VERSION ""

NS_ :

BS_:

BU_: LDS4 SCU_B SCU_A GCU_B GCU_A StreetDrone
VAL_TABLE_ GCU_A_State 15 "ERROR" 5 "SAFE_GCU_B_DISABLED" 4 "SAFE" 3 "AUTO" 2 "MANUAL" 1 "IN IT" 0 "UNKNOWN" ;
VAL_TABLE_ False_True 597 "True" 0 "False" ;

BO_ 50 SCU_B_Data_3: 8 SCU_B
 SG_ Brake_Torque_1_Control : 0|16@1- (0.01,0) [-327.68|327.67] "Nm"  LDS4,GCU_B,GCU_A

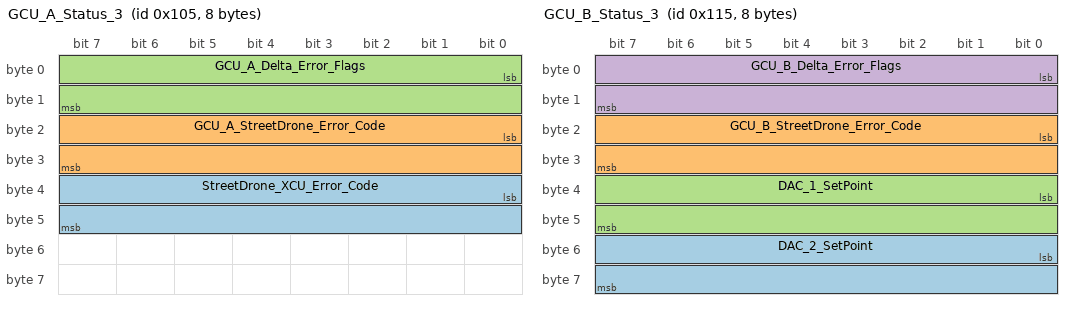
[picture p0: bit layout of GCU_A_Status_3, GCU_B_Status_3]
BO_ 261 GCU_A_Status_3: 8 GCU_A
 SG_ StreetDrone_XCU_Error_Code : 32|16@1+ (1,0) [0|65535] ""  LDS4,GCU_B
 SG_ GCU_A_StreetDrone_Error_Code : 16|16@1+ (1,0) [0|65535] ""  LDS4,GCU_B
 SG_ GCU_A_Delta_Error_Flags : 0|16@1+ (1,0) [0|65535] ""  LDS4,GCU_B

BO_ 277 GCU_B_Status_3: 8 GCU_B
 SG_ DAC_2_SetPoint : 48|16@1+ (1,0) [0|65535] ""  LDS4,GCU_A
 SG_ GCU_B_StreetDrone_Error_Code : 16|16@1+ (1,0) [0|65535] ""  LDS4,GCU_A
 SG_ DAC_1_SetPoint : 32|16@1+ (1,0) [0|65535] ""  LDS4,GCU_A
 SG_ GCU_B_Delta_Error_Flags : 0|16@1+ (1,0) [0|65535] ""  LDS4,GCU_A

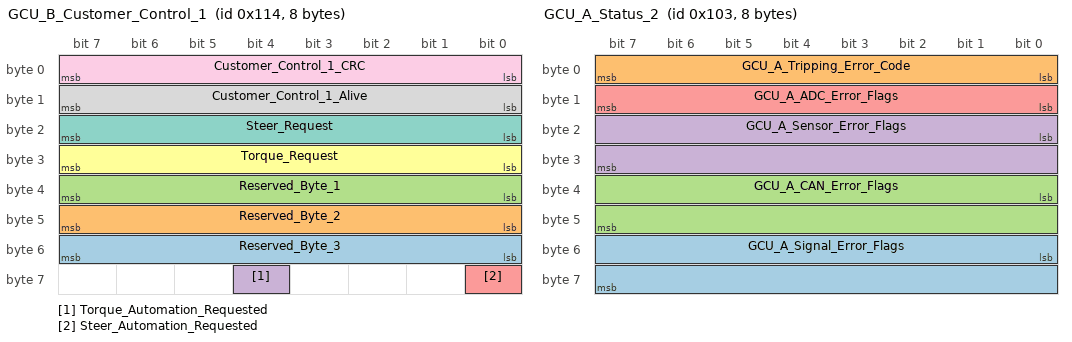
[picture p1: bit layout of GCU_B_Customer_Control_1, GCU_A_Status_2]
BO_ 276 GCU_B_Customer_Control_1: 8 GCU_B
 SG_ Reserved_Byte_3 : 55|8@0- (1,0) [0|255] ""  LDS4,GCU_A
 SG_ Reserved_Byte_2 : 47|8@0+ (1,0) [0|255] ""  LDS4,GCU_A
 SG_ Reserved_Byte_1 : 39|8@0+ (1,0) [0|255] ""  LDS4,GCU_A
 SG_ Torque_Automation_Requested : 60|1@0+ (1,0) [0|1] ""  LDS4,GCU_A
 SG_ Steer_Automation_Requested : 56|1@0+ (1,0) [0|1] ""  LDS4,GCU_A
 SG_ Torque_Request : 31|8@0- (1,0) [-100|100] "%"  LDS4,GCU_A,StreetDrone
 SG_ Steer_Request : 23|8@0- (1,0) [-100|100] "%"  LDS4,GCU_A,StreetDrone
 SG_ Customer_Control_1_Alive : 15|8@0+ (1,0) [0|255] ""  LDS4,GCU_A,StreetDrone
 SG_ Customer_Control_1_CRC : 7|8@0+ (1,0) [0|255] ""  LDS4,GCU_A,StreetDrone

BO_ 259 GCU_A_Status_2: 8 GCU_A
 SG_ GCU_A_Signal_Error_Flags : 48|16@1+ (1,0) [0|65535] ""  LDS4,GCU_B
 SG_ GCU_A_Tripping_Error_Code : 7|8@0+ (1,0) [0|255] ""  LDS4,GCU_B
 SG_ GCU_A_CAN_Error_Flags : 32|16@1+ (1,0) [0|65535] ""  LDS4,GCU_B
 SG_ GCU_A_Sensor_Error_Flags : 16|16@1+ (1,0) [0|65535] ""  LDS4,GCU_B
 SG_ GCU_A_ADC_Error_Flags : 15|8@0+ (1,0) [0|255] ""  LDS4,GCU_B

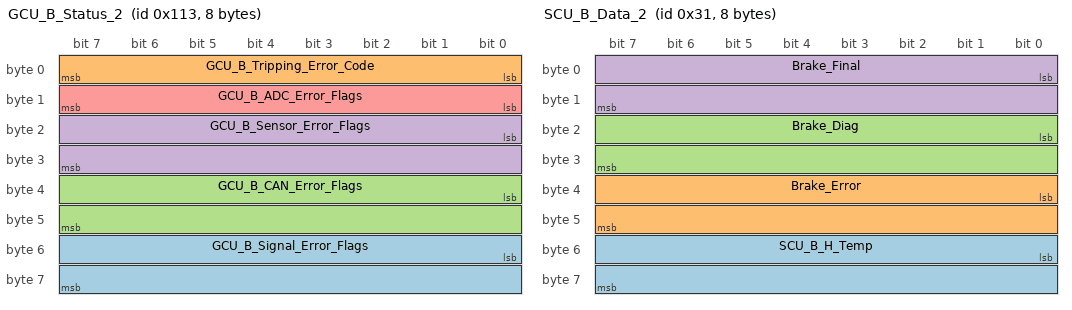
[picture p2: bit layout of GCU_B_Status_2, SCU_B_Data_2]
BO_ 275 GCU_B_Status_2: 8 GCU_B
 SG_ GCU_B_Signal_Error_Flags : 48|16@1+ (1,0) [0|65535] ""  LDS4,GCU_A
 SG_ GCU_B_Tripping_Error_Code : 7|8@0+ (1,0) [0|255] ""  LDS4,GCU_A
 SG_ GCU_B_CAN_Error_Flags : 32|16@1+ (1,0) [0|65535] ""  LDS4,GCU_A
 SG_ GCU_B_Sensor_Error_Flags : 16|16@1+ (1,0) [0|65535] ""  LDS4,GCU_A
 SG_ GCU_B_ADC_Error_Flags : 15|8@0+ (1,0) [0|255] ""  LDS4,GCU_A

BO_ 113 SCU_AB_Control_A: 8 GCU_A
 SG_ Brake_Enable_A : 39|8@0+ (1,0) [0|255] ""  LDS4,GCU_B,SCU_A,SCU_B
 SG_ Steer_Enable_A : 7|8@0+ (1,0) [0|255] ""  LDS4,GCU_B,SCU_A,SCU_B

BO_ 49 SCU_B_Data_2: 8 SCU_B
 SG_ SCU_B_H_Temp : 48|16@1- (1,0) [0|0] "?"  LDS4,GCU_B,GCU_A
 SG_ Brake_Error : 32|16@1- (0.1,0) [-3276.8|3276.7] "%"  LDS4,GCU_B,GCU_A
 SG_ Brake_Diag : 16|16@1+ (1,0) [0|65535] ""  LDS4,GCU_B,GCU_A
 SG_ Brake_Final : 0|16@1- (0.01,0) [-327.68|327.67] "%"  LDS4,GCU_B,GCU_A

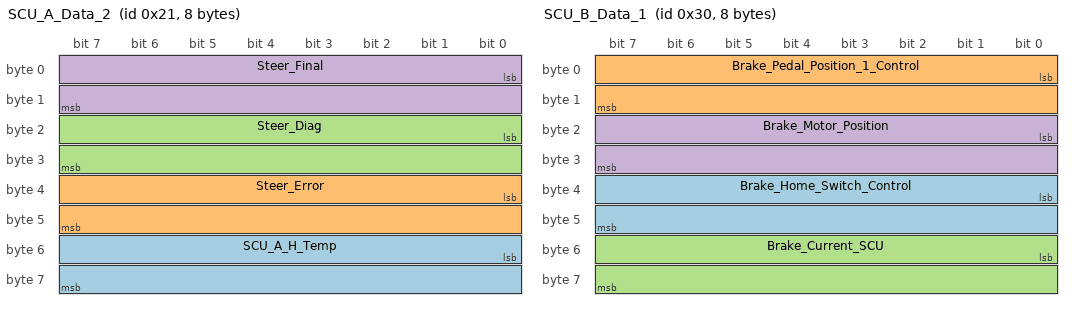
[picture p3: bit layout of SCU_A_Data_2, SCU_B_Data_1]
BO_ 33 SCU_A_Data_2: 8 SCU_A
 SG_ SCU_A_H_Temp : 48|16@1- (1,0) [0|0] "?"  LDS4,GCU_B,GCU_A
 SG_ Steer_Error : 32|16@1- (0.1,0) [-3276.8|3276.7] "%"  LDS4,GCU_B,GCU_A
 SG_ Steer_Diag : 16|16@1+ (1,0) [0|65535] ""  LDS4,GCU_B,GCU_A
 SG_ Steer_Final : 0|16@1- (0.01,0) [-327.68|327.67] "%"  LDS4,GCU_B,GCU_A

BO_ 48 SCU_B_Data_1: 8 SCU_B
 SG_ Brake_Home_Switch_Control : 32|16@1- (0.001,0) [-32.768|32.767] "V"  LDS4,GCU_B,GCU_A
 SG_ Brake_Pedal_Position_1_Control : 0|16@1- (0.1,0) [-327.68|327.67] "%"  LDS4,GCU_B,GCU_A
 SG_ Brake_Current_SCU : 48|16@1- (0.01,0) [-327.68|327.67] "A"  LDS4,GCU_B,GCU_A
 SG_ Brake_Motor_Position : 16|16@1- (0.1,0) [-3276.8|3276.7] "%"  LDS4,GCU_B,GCU_A

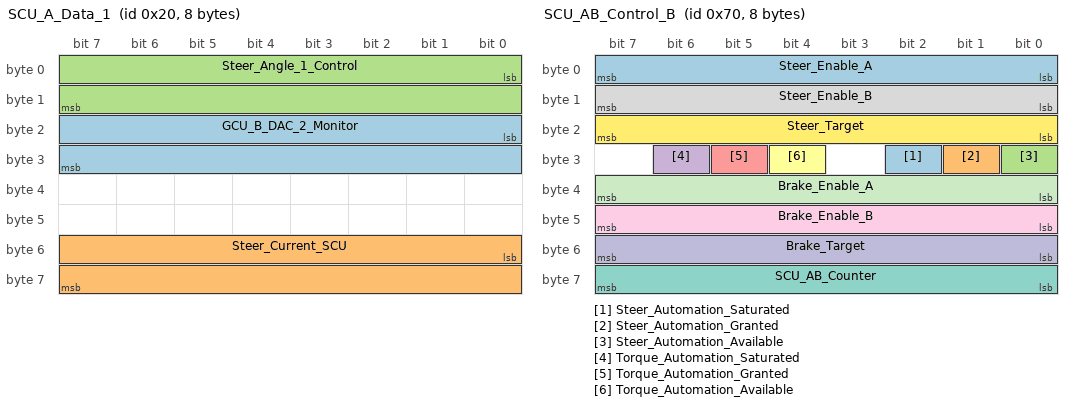
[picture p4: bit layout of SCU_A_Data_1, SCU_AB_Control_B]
BO_ 32 SCU_A_Data_1: 8 SCU_A
 SG_ GCU_B_DAC_2_Monitor : 16|16@1- (0.001,0) [-32.768|32.767] "V"  LDS4,GCU_B,GCU_A
 SG_ Steer_Current_SCU : 48|16@1- (0.01,0) [-327.68|327.67] "A"  LDS4,GCU_B,GCU_A
 SG_ Steer_Angle_1_Control : 0|16@1- (0.1,0) [-3276.8|3276.7] "%"  LDS4,GCU_B,GCU_A

BO_ 112 SCU_AB_Control_B: 8 GCU_B
 SG_ Steer_Automation_Saturated : 26|1@1- (1,0) [0|0] ""  LDS4,GCU_A,SCU_A,SCU_B
 SG_ Steer_Automation_Granted : 25|1@1- (1,0) [0|0] ""  LDS4,GCU_A,SCU_A,SCU_B
 SG_ Steer_Automation_Available : 24|1@1- (1,0) [0|0] ""  LDS4,GCU_A,SCU_A,SCU_B
 SG_ Torque_Automation_Saturated : 30|1@1- (1,0) [0|0] ""  LDS4,GCU_A,SCU_A,SCU_B
 SG_ Torque_Automation_Granted : 29|1@1- (1,0) [0|0] ""  LDS4,GCU_A,SCU_A,SCU_B
 SG_ Torque_Automation_Available : 28|1@1- (1,0) [0|0] ""  LDS4,GCU_A,SCU_A,SCU_B
 SG_ SCU_AB_Counter : 63|8@0+ (1,0) [0|255] ""  LDS4,GCU_A,SCU_A,SCU_B
 SG_ Steer_Enable_B : 15|8@0+ (1,0) [0|255] ""  LDS4,GCU_A,SCU_A,SCU_B
 SG_ Brake_Enable_B : 47|8@0+ (1,0) [0|255] ""  LDS4,GCU_A,SCU_A,SCU_B
 SG_ Brake_Target : 55|8@0- (1,0) [-128|127] "Bar"  LDS4,GCU_A,SCU_A,SCU_B
 SG_ Brake_Enable_A : 39|8@0+ (1,0) [0|255] ""  LDS4,GCU_A,SCU_A,SCU_B
 SG_ Steer_Target : 23|8@0- (1,0) [-128|127] "%"  LDS4,GCU_A,SCU_A,SCU_B
 SG_ Steer_Enable_A : 7|8@0+ (1,0) [0|255] ""  LDS4,GCU_A,SCU_A,SCU_B

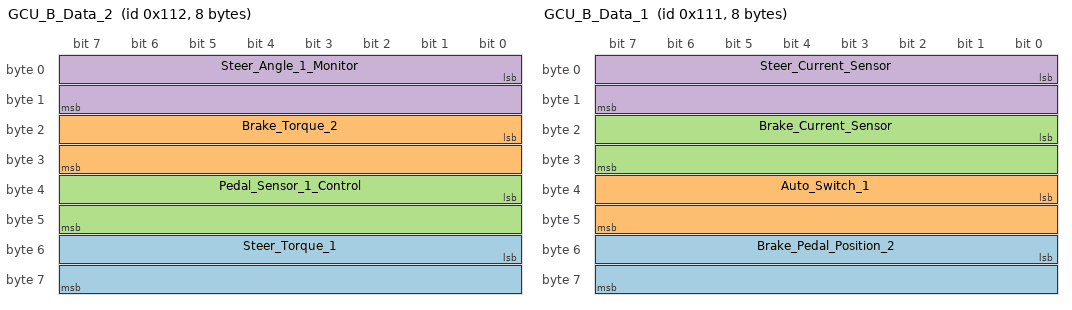
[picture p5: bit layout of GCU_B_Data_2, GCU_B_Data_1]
BO_ 274 GCU_B_Data_2: 8 GCU_B
 SG_ Steer_Torque_1 : 48|16@1- (0.1,0) [-3276.8|3276.7] "Nm"  LDS4,GCU_A
 SG_ Brake_Torque_2 : 16|16@1- (0.01,0) [-327.68|327.67] "Nm"  LDS4,GCU_A
 SG_ Pedal_Sensor_1_Control : 32|16@1- (0.1,0) [-3276.8|3276.7] "%"  LDS4,GCU_A
 SG_ Steer_Angle_1_Monitor : 0|16@1- (0.1,0) [-3276.8|3276.7] "%"  LDS4,GCU_A

BO_ 273 GCU_B_Data_1: 8 GCU_B
 SG_ Brake_Pedal_Position_2 : 48|16@1- (0.1,0) [-3276.8|3276.7] "%"  LDS4,GCU_A
 SG_ Auto_Switch_1 : 32|16@1- (0.001,0) [-32.768|32.767] "V"  LDS4,GCU_A
 SG_ Brake_Current_Sensor : 16|16@1- (0.01,0) [-327.68|327.67] "A"  LDS4,GCU_A
 SG_ Steer_Current_Sensor : 0|16@1- (0.01,0) [-327.68|327.67] "A"  LDS4,GCU_A

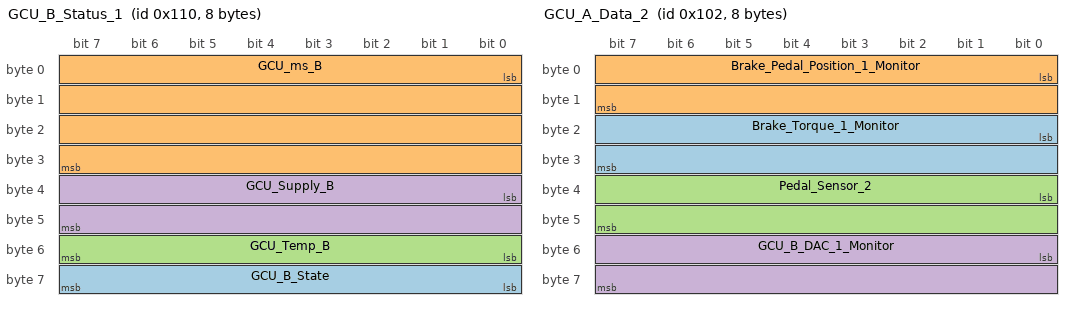
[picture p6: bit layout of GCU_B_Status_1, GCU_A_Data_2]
BO_ 272 GCU_B_Status_1: 8 GCU_B
 SG_ GCU_B_State : 63|8@0+ (1,0) [0|255] ""  LDS4,GCU_A
 SG_ GCU_ms_B : 0|32@1+ (1,0) [0|4294967295] "ms"  LDS4,GCU_A
 SG_ GCU_Temp_B : 48|8@1- (1,0) [-128|127] "degC"  LDS4,GCU_A
 SG_ GCU_Supply_B : 32|16@1- (0.01,0) [-327.68|327.67] "V"  LDS4,GCU_A

BO_ 258 GCU_A_Data_2: 8 GCU_A
 SG_ Brake_Torque_1_Monitor : 16|16@1- (0.01,0) [-327.68|327.67] "Nm"  LDS4,GCU_B
 SG_ Brake_Pedal_Position_1_Monitor : 0|16@1- (0.1,0) [-3276.8|3276.7] "%"  LDS4,GCU_B
 SG_ Pedal_Sensor_2 : 32|16@1- (0.1,0) [-3276.8|3276.7] "%"  LDS4,GCU_B
 SG_ GCU_B_DAC_1_Monitor : 48|16@1- (0.001,0) [-32.768|32.767] "V"  LDS4,GCU_B

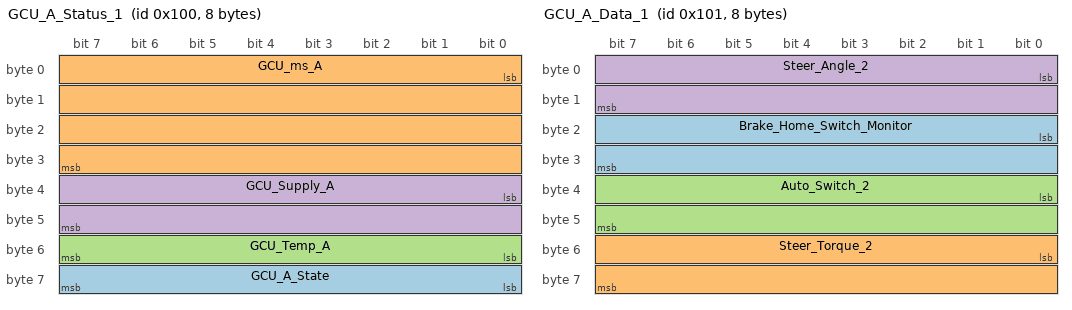
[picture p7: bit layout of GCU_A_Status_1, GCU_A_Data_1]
BO_ 256 GCU_A_Status_1: 8 GCU_A
 SG_ GCU_A_State : 63|8@0+ (1,0) [0|255] ""  LDS4,GCU_B
 SG_ GCU_ms_A : 0|32@1+ (1,0) [0|4294967295] "ms"  LDS4,GCU_B
 SG_ GCU_Temp_A : 48|8@1- (1,0) [-128|127] "degC"  LDS4,GCU_B
 SG_ GCU_Supply_A : 32|16@1- (0.01,0) [-327.68|327.67] "V"  LDS4,GCU_B

BO_ 257 GCU_A_Data_1: 8 GCU_A
 SG_ Brake_Home_Switch_Monitor : 16|16@1- (0.001,0) [-32.768|32.767] "V"  LDS4,GCU_B
 SG_ Steer_Torque_2 : 48|16@1- (0.1,0) [-3276.8|3276.7] "Nm"  LDS4,GCU_B
 SG_ Auto_Switch_2 : 32|16@1- (0.001,0) [-32.768|32.767] "V"  LDS4,GCU_B
 SG_ Steer_Angle_2 : 0|16@1- (0.1,0) [-3276.8|3276.7] "%"  LDS4,GCU_B

BA_DEF_ BU_  "NodeLayerModules" STRING ;
BA_DEF_  "BusType" STRING ;
BA_DEF_ BO_  "GenMsgCycleTime" INT 1 50000;
BA_DEF_ BO_  "GenMsgDelayTime" INT 1 1000;
BA_DEF_ BO_  "GenMsgNrOfRepetitions" INT 1 999999;
BA_DEF_DEF_  "NodeLayerModules" "CANoeILNLVector.dll";
BA_DEF_DEF_  "BusType" "CAN";
BA_DEF_DEF_  "GenMsgCycleTime" 100;
BA_DEF_DEF_  "GenMsgDelayTime" 1;
BA_DEF_DEF_  "GenMsgNrOfRepetitions" 1;
BA_ "GenMsgCycleTime" BO_ 274 2;
BA_ "GenMsgCycleTime" BO_ 273 2;
BA_ "GenMsgCycleTime" BO_ 272 1;
BA_ "GenMsgCycleTime" BO_ 258 2;
BA_ "GenMsgCycleTime" BO_ 256 1;
BA_ "GenMsgCycleTime" BO_ 257 2;
VAL_ 113 Brake_Enable_A 597 "True" 0 "False" ;
VAL_ 113 Steer_Enable_A 597 "True" 0 "False" ;
VAL_ 112 Steer_Enable_B 597 "True" 0 "False" ;
VAL_ 112 Brake_Enable_B 597 "True" 0 "False" ;
VAL_ 112 Brake_Enable_A 597 "True" 0 "False" ;
VAL_ 112 Steer_Enable_A 597 "True" 0 "False" ;
VAL_ 256 GCU_A_State 15 "ERROR" 5 "SAFE_GCU_B_DISABLED" 4 "SAFE" 3 "AUTO" 2 "MANUAL" 1 "IN IT" 0 "UNKNOWN" ;
